# PIC32CM1216LS60100 device description
Architecture: CORTEX-M23; Family: PIC32CM; Series: PIC32CMLS60
Registers are 32-bit, read-write, reset 0x0 unless marked. A register's access mark holds for its fields unless they carry their own. Offsets are from the block's base; [hi:lo] are bit positions; lines under a group give offsets from that group; {n}, {i} and the like mark numbered series; 'fields as' and 'values as' point back to an identical list.

## DWT — Data Watchpoint and Trace
Instances: DWT 0xE0001000
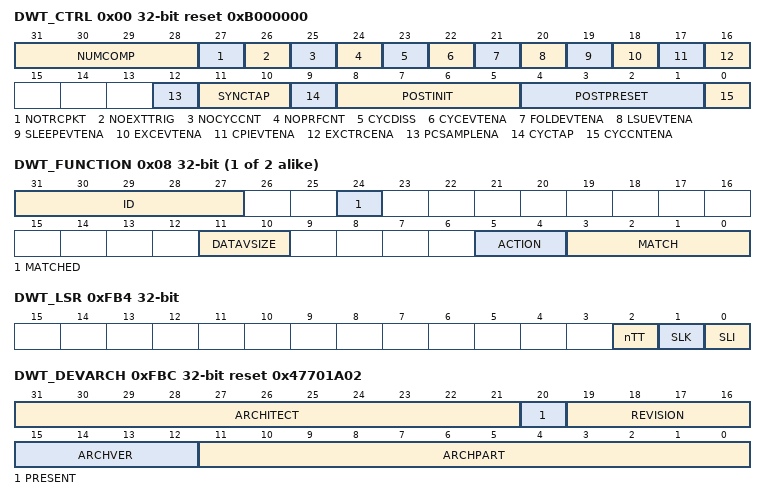
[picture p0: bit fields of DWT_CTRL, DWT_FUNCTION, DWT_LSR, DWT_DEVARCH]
0x00 DWT_CTRL reset 0xB000000 — DWT Control Register
  [31:28] NUMCOMP — Number of comparators
  [27] NOTRCPKT — No trace packets
  [26] NOEXTTRIG — No external triggers
  [25] NOCYCCNT — No cycle count
  [24] NOPRFCNT — No profile counters
  [23] CYCDISS — Cycle counter disabled secure
  [22] CYCEVTENA — Cycle event enable
  [21] FOLDEVTENA — Fold event enable
  [20] LSUEVTENA — LSU event enable
  [19] SLEEPEVTENA — Sleep event enable
  [18] EXCEVTENA — Exception event enable
  [17] CPIEVTENA — CPI event enable
  [16] EXCTRCENA — Exception trace enable
  [12] PCSAMPLENA — PC sample enable
  [11:10] SYNCTAP — Synchronization tap
  [9] CYCTAP — Cycle count tap
  [8:5] POSTINIT — POSTCNT initial
  [4:1] POSTPRESET — POSTCNT preset
  [0] CYCCNTENA — CYCCNT enable
0x1C DWT_PCSR ro reset not defined — DWT Program Counter Sample Register
  [31:0] EIASAMPLE — Executed instruction address sample
{0x20+0x10*i} COMPARATOR[{i}] (i=0..1) group
  0x00 DWT_COMP reset not defined — DWT Comparator Register n
    [31:0] VALUE — Cycle/PC/data value or data address
  0x08 DWT_FUNCTION reset not defined — DWT Function Register x
    [31:27] ID — Identify capability
    [24] MATCHED — Comparator matched
    [11:10] DATAVSIZE — Data value size
    [5:4] ACTION — Action on match
    [3:0] MATCH — Match type
0xFB0 DWT_LAR wo reset not defined — DWT Software Lock Access Register
  [31:0] KEY — Lock access control
    0xC5ACCE55=UNLOCK (Unlock key value)
0xFB4 DWT_LSR ro reset not defined — DWT Software Lock Status Register
  [2] nTT — Not thirty-two bit
  [1] SLK — Software Lock status
  [0] SLI — Software Lock implemented
0xFBC DWT_DEVARCH ro reset 0x47701A02 — DWT Device Architecture Register
  [31:21] ARCHITECT
  [20] PRESENT — DEVARCH Present
  [19:16] REVISION
  [15:12] ARCHVER — Architecture Version
  [11:0] ARCHPART — Architecture Part
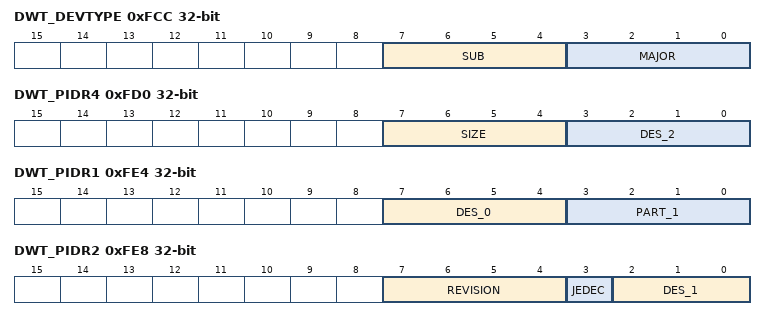
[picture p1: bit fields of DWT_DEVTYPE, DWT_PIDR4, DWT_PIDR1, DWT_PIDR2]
0xFCC DWT_DEVTYPE ro — DWT Device Type Register
  [7:4] SUB — Sub-type
  [3:0] MAJOR — Major type
0xFD0 DWT_PIDR4 ro reset not defined — DWT Peripheral Identification Register 4
  [7:4] SIZE — 4KB count
  [3:0] DES_2 — JEP106 continuation code
{0xFC0+4i} DWT_PIDR{i} ro (i=5..7) — DWT Peripheral Identification Register {i}
0xFE0 DWT_PIDR0 ro reset not defined — DWT Peripheral Identification Register 0
  [7:0] PART_0 — Part number bits[7:0]
0xFE4 DWT_PIDR1 ro reset not defined — DWT Peripheral Identification Register 1
  [7:4] DES_0 — JEP106 identification code bits [3:0]
  [3:0] PART_1 — Part number bits[11:8]
0xFE8 DWT_PIDR2 ro reset not defined — DWT Peripheral Identification Register 2
  [7:4] REVISION — Component revision
  [3] JEDEC — JEDEC assignee value is used
  [2:0] DES_1 — JEP106 identification code bits[6:4]
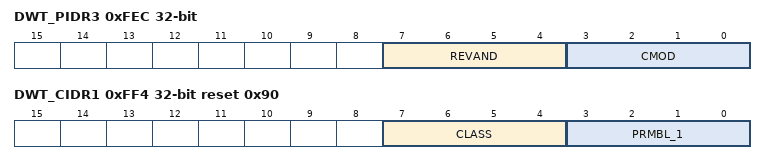
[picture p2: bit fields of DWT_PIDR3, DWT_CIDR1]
0xFEC DWT_PIDR3 ro reset not defined — DWT Peripheral Identification Register 3
  [7:4] REVAND
  [3:0] CMOD — Customer Modified
0xFF0 DWT_CIDR0 ro reset 0xD — DWT Component Identification Register 0
  [7:0] PRMBL_0 — CoreSight component identification preamble
0xFF4 DWT_CIDR1 ro reset 0x90 — DWT Component Identification Register 1
  [7:4] CLASS — CoreSight component class
  [3:0] PRMBL_1 — CoreSight component identification preamble
0xFF8 DWT_CIDR2 ro reset 0x5 — DWT Component Identification Register 2
  [7:0] PRMBL_2 — CoreSight component identification preamble
0xFFC DWT_CIDR3 ro reset 0xB1 — DWT Component Identification Register 3
  [7:0] PRMBL_3 — CoreSight component identification preamble

## EIC — External Interrupt Controller
Instances: EIC 0x40002800, EIC_SEC 0x40002A00
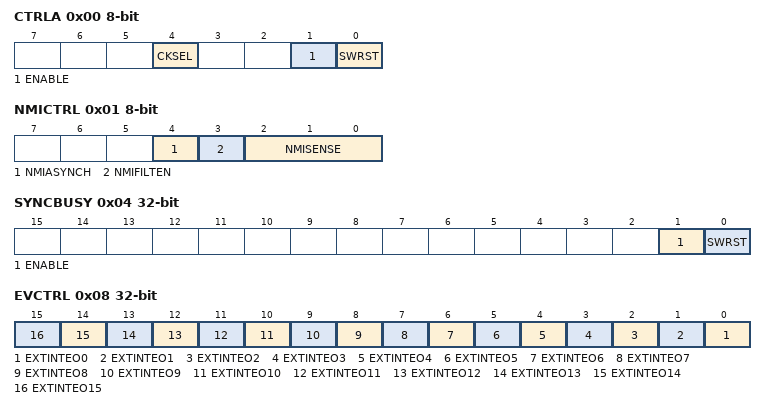
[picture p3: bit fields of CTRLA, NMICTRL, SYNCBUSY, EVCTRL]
0x00 CTRLA 8-bit (WSYNC) — Control A
  [4] CKSEL — Clock Selection
    0=CLK_GCLK (Clocked by GCLK); 1=CLK_ULP32K (Clocked by ULP32K)
  [1] ENABLE
  [0] SWRST — Software Reset
0x01 NMICTRL 8-bit — Non-Maskable Interrupt Control
  [4] NMIASYNCH — Asynchronous Edge Detection Mode
    0=SYNC (Edge detection is clock synchronously operated); 1=ASYNC (Edge detection is clock asynchronously operated)
  [3] NMIFILTEN — Non-Maskable Interrupt Filter Enable
  [2:0] NMISENSE — Non-Maskable Interrupt Sense Configuration
    0=NONE (No detection); 1=RISE (Rising-edge detection); 2=FALL (Falling-edge detection); 3=BOTH (Both-edges detection); 4=HIGH (High-level detection); 5=LOW (Low-level detection)
0x02 NMIFLAG 8-bit (atomic clear) — Non-Maskable Interrupt Flag Status and Clear
  [0] NMI — Non-Maskable Interrupt
0x04 SYNCBUSY ro — Synchronization Busy
  [1] ENABLE — Enable Synchronization Busy Status
  [0] SWRST — Software Reset Synchronization Busy Status
0x08 EVCTRL — Event Control
  [n] EXTINTEO{n} (n=0..15) — External Interrupt {n} Event Output Enable
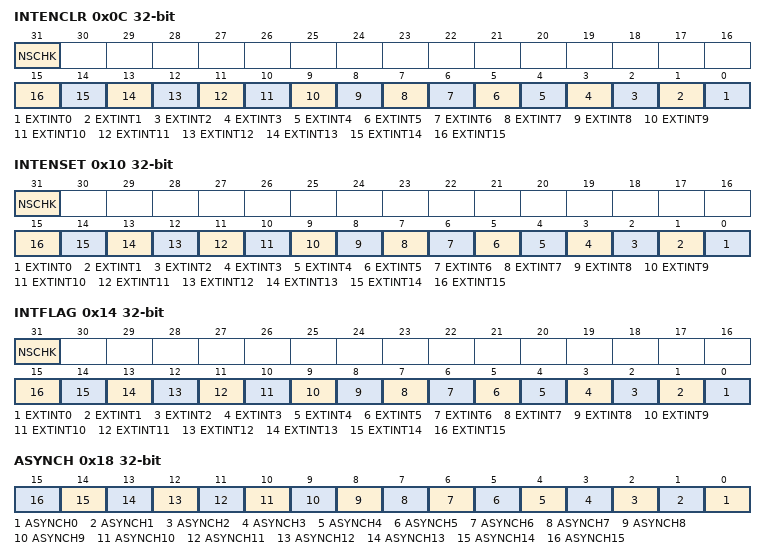
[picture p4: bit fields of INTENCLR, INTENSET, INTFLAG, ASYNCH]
0x0C INTENCLR (atomic clear) — Interrupt Enable Clear
  [31] NSCHK — Non-secure Check Interrupt Enable
  [n] EXTINT{n} (n=0..15) — External Interrupt {n} Enable
0x10 INTENSET (atomic set) — Interrupt Enable Set
  fields as INTENCLR
0x14 INTFLAG (atomic clear) — Interrupt Flag Status and Clear
  [31] NSCHK — Non-secure Check Interrupt
  [n] EXTINT{n} (n=0..15) — External Interrupt {n}
0x18 ASYNCH — External Interrupt Asynchronous Mode
  [all] fields
    values as NMICTRL.NMIASYNCH
  [n] ASYNCH{n} (n=0..15) — Asynchronous Edge Detection Mode of EXTINT{n}
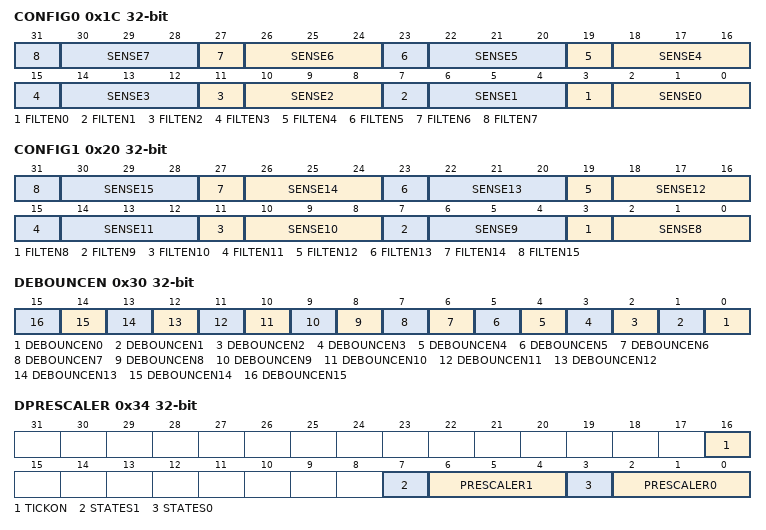
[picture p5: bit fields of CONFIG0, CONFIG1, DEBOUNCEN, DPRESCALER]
0x1C CONFIG0 — External Interrupt Sense Configuration
  [4n+3] FILTEN{n} (n=0..7) — Filter Enable {n}
  [4n+2:4n] SENSE{n} (n=0..7) — Input Sense Configuration {n}
    0=NONE (No detection); 1=RISE (Rising edge detection); 2=FALL (Falling edge detection); 3=BOTH (Both edges detection); 4=HIGH (High level detection); 5=LOW (Low level detection)
0x20 CONFIG1 — External Interrupt Sense Configuration
  [4n-29] FILTEN{n} (n=8..15) — Filter Enable {n}
  [4n-30:4n-32] SENSE{n} (n=8..15) — Input Sense Configuration {n}
    values as CONFIG0.SENSE0
0x30 DEBOUNCEN — Debouncer Enable
  [n] DEBOUNCEN{n} (n=0..15) — Debouncer Enable of EXTINT{n}
0x34 DPRESCALER — Debouncer Prescaler
  [16] TICKON — Pin Sampler frequency selection
    0=CLK_GCLK_EIC (Clocked by GCLK); 1=CLK_LFREQ (Clocked by Low Frequency Clock)
  [7] STATES1 — Debouncer number of states
    0=LFREQ3 (3 low frequency samples); 1=LFREQ7 (7 low frequency samples)
  [6:4] PRESCALER1 — Debouncer Prescaler
    0=DIV2 (EIC clock divided by 2); 1=DIV4 (EIC clock divided by 4); 2=DIV8 (EIC clock divided by 8); 3=DIV16 (EIC clock divided by 16); 4=DIV32 (EIC clock divided by 32); 5=DIV64 (EIC clock divided by 64); 6=DIV128 (EIC clock divided by 128); 7=DIV256 (EIC clock divided by 256)
  [3] STATES0 — Debouncer number of states
    values as STATES1
  [2:0] PRESCALER0 — Debouncer Prescaler
    values as PRESCALER1
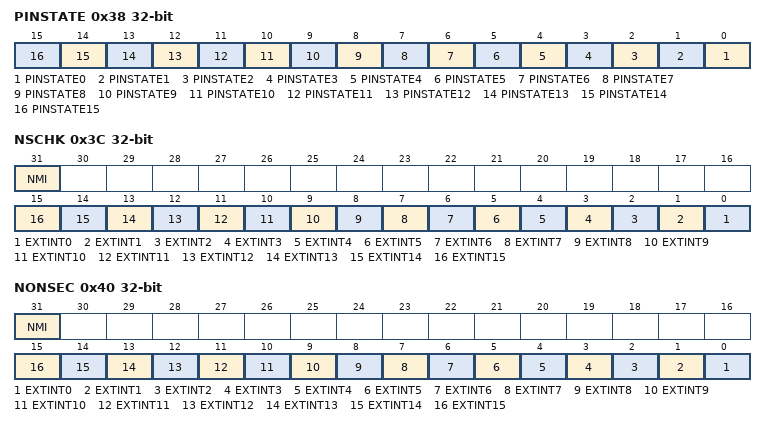
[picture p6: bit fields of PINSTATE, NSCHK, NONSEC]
0x38 PINSTATE ro
  [n] PINSTATE{n} (n=0..15) — Pin State of EXTINT{n}
0x3C NSCHK — Non-secure Interrupt Check Enable
  [31] NMI — Non-Maskable External Interrupt Nonsecure Check Enable
  [n] EXTINT{n} (n=0..15) — External Interrupt {n} Nonsecure Check Enable
0x40 NONSEC — Non-secure Interrupt
  [31] NMI — Non-Maskable Interrupt Nonsecure Enable
  [n] EXTINT{n} (n=0..15) — External Interrupt {n} Nonsecure Enable

## Notices in the file
Copyright (c) 2019 Microchip Technology Inc.
SPDX-License-Identifier: Apache-2.0
Licensed under the Apache License, Version 2.0 (the "License");
you may not use this file except in compliance with the License.
You may obtain a copy of the License at
http://www.apache.org/licenses/LICENSE-2.0
Unless required by applicable law or agreed to in writing, software
distributed under the License is distributed on an "AS IS" BASIS,
WITHOUT WARRANTIES OR CONDITIONS OF ANY KIND, either express or implied.
See the License for the specific language governing permissions and
limitations under the License.
